# CONTROLSS_PWMXBAR_CONTROLSS_502D1000h register map
Vendor: Texas Instruments
Peripheral module from a debugger description file (folder AM261x).
Registers are 32-bit, read-write, reset 0x0 unless marked. A register's access mark holds for its fields unless they carry their own. Offsets are as the file gives them; lines under a group give offsets from that group; [hi:lo] are bit positions; {n}, {i} and the like mark numbered series; 'fields as' and 'values as' point back to an identical list; <NAME> marks a mode.

## CONTROLSS
0x10 CONTROLSS_PWMXBAR_STATUS ro — Output Signal Status.
  [29:0] PWMXBAR_STATUS_STS — Output Signal Status
0x14 CONTROLSS_PWMXBAR_FLAGINVERT — Output Signal Invert Before Latch.
  [29:0] PWMXBAR_FLAGINVERT_INVERT — Output Signal Invert Before Latch
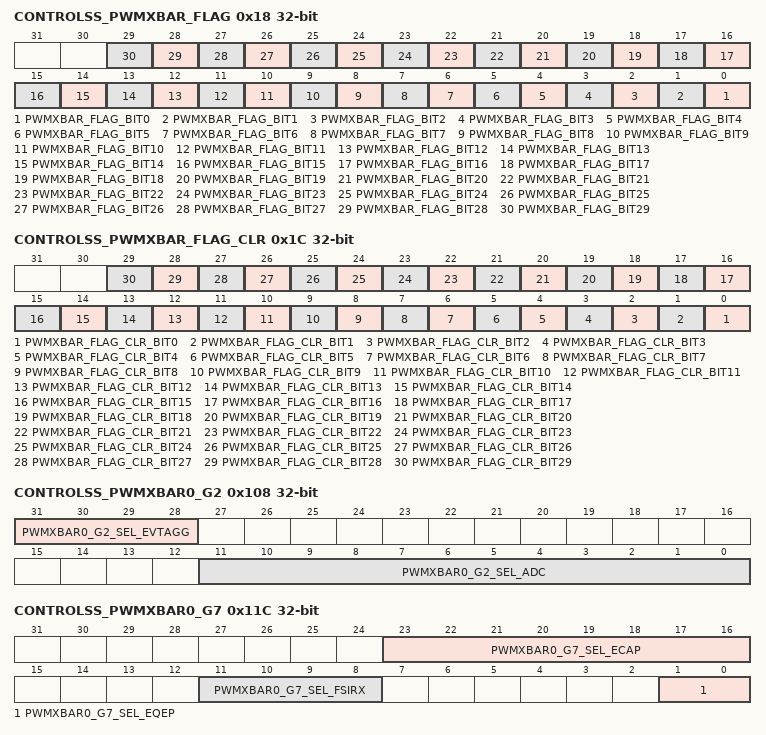
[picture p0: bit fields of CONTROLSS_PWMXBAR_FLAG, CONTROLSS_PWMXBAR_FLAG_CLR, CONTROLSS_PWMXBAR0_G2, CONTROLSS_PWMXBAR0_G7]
0x18 CONTROLSS_PWMXBAR_FLAG access not given — Output Signal Latched Flag.
  [n] PWMXBAR_FLAG_BIT{n} (n=0..29) — Output Signal Latched Flag (access R/W1TC)
0x1C CONTROLSS_PWMXBAR_FLAG_CLR — Output Signal Latched Flag Clear.
  [n] PWMXBAR_FLAG_CLR_BIT{n} (n=0..29) — Output Signal Latched Flag Clear
{0x100+0x40*i} CONTROLSS_PWMXBAR{i}_G0 (i=0..15) — PWM XBAR {i} Input Select.
  [17:0] PWMXBAR{i}_G0_SEL — PWM XBAR{i} G0 Input Select0:CMP12SS0.CTRIPL1:CMP12SS0.CTRIPH2:CMP12SS1.CTRIPL3:CMP12SS1.CTRIPH4:CMP12SS2.CTRIPL5:CMP12SS2.CTRIPH6:CMP12SS3.CTRIPL7:CMP12SS3.CTRIPH8:CMP12SS4.CTRIPL9:CMP12SS4.CTRIPH10:CMP12SS5.CTRIPL11:CMP12SS5.CTRIPH12:CMP12SS6.CTRIPL13:CMP12SS6.CTRIPH14:CMP12SS7.CTRIPL15:CMP12SS7.CTRIPH16:CMP12SS8.CTRIPL17:CMP12SS8.CTRIPH
{0x104+0x40*i} CONTROLSS_PWMXBAR{i}_G1 (i=0..29) — PWM XBAR {i} Input Select.
  [23:0] PWMXBAR{i}_G1_SEL — PWM XBAR{i} G1 Input Select0:SDFM0.FILT1CEVT11:SDFM0.FILT1CEVT22:SDFM0.FILT1COMPHZ3:SDFM0.FILT2CEVT14:SDFM0.FILT2CEVT25:SDFM0.FILT2COMPHZ6:SDFM0.FILT3CEVT17:SDFM0.FILT3CEVT28:SDFM0.FILT3COMPHZ9:SDFM0.FILT4CEVT110:SDFM0.FILT4CEVT211:SDFM0.FILT4COMPHZ12:SDFM1.FILT1CEVT113:SDFM1.FILT1CEVT214:SDFM1.FILT1COMPHZ15:SDFM1.FILT2CEVT116:SDFM1.FILT2CEVT217:SDFM1.FILT2COMPHZ18:SDFM1.FILT3CEVT119:SDFM1.FILT3CEVT220:SDFM1.FILT3COMPHZ21:SDFM1.FILT4CEVT122:SDFM1.FILT4CEVT223:SDFM1.FILT4COMPHZ
0x108 CONTROLSS_PWMXBAR0_G2 — PWM XBAR 0 Input Select.
  [31:28] PWMXBAR0_G2_SEL_EVTAGG — PWM XBAR0 G2 Input Select 2831:ADC_ASC_CHECKEVENT[3:0]
  [11:0] PWMXBAR0_G2_SEL_ADC — PWM XBAR0 G2 Input Select1:ADC0.EVT22:ADC0.EVT33:ADC0.EVT44:ADC1.EVT15:ADC1.EVT26:ADC1.EVT37:ADC1.EVT48:ADC2.EVT19:ADC2.EVT210:ADC2.EVT311:ADC2.EVT4
{0x10C+0x40*i} CONTROLSS_PWMXBAR{i}_G3 (i=0..29) — PWM XBAR {i} Input Select.
  [31:0] PWMXBAR{i}_G3_SEL — PWM XBAR{i} G3 input bit select. Input source is INPUT XBAR.1:INPUT XBAR output bit[x] selected0:INPUT XBAR output bit[x] is de-selected
{0x110+0x40*i} CONTROLSS_PWMXBAR{i}_G4 (i=0..29) — PWM XBAR {i} Input Select.
  [9:0] PWMXBAR{i}_G4_SEL — PWM XBAR{i} G4 input bit select. Input source is PWM TRIPOUT.1:PWM TRIPOUT bit[x] selected0:PWM TRIPOUT bit[x] is de-selected
{0x114+0x40*i} CONTROLSS_PWMXBAR{i}_G5 (i=0..29) — PWM XBAR {i} Input Select.
  [9:0] PWMXBAR{i}_G5_SEL — PWM XBAR{i} G5 input bit select. Input source is PWM DEL TRIP1:PWM DEL TRIP bit[x] selected0:PWM DEL TRIP bit[x] is de-selected
{0x118+0x40*i} CONTROLSS_PWMXBAR{i}_G6 (i=0..29) — PWM XBAR {i} Input Select.
  [9:0] PWMXBAR{i}_G6_SEL — PWM XBAR{i} G6 input bit select. Input source is PWM DEL ACTIVE1:PWM DEL ACTIVE bit[x] selected0:PWM DEL ACTIVE bit[x] is de-selected
0x11C CONTROLSS_PWMXBAR0_G7 — PWM XBAR 0 Input Select.
  [23:16] PWMXBAR0_G7_SEL_ECAP — PWM XBAR0 G7 Input Select2316:ECAP[7:0].TRIPOUT
  [11:8] PWMXBAR0_G7_SEL_FSIRX — PWM XBAR0 G7 Input Select8:FSIRX0.RX_TRIG09:FSIRX0.RX_TRIG110:FSIRX0.RX_TRIG211:FSIRX0.RX_TRIG3
  [1:0] PWMXBAR0_G7_SEL_EQEP — PWM XBAR0 G7 Input Select0:EQEP0.ERR1:EQEP1.ERR
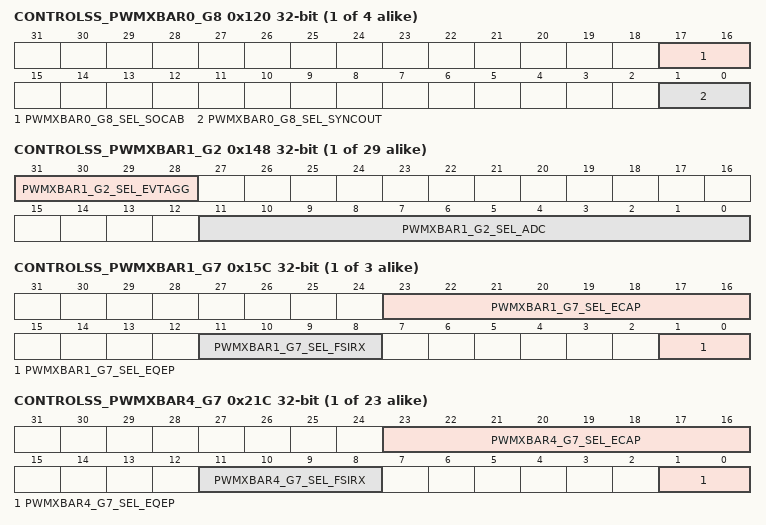
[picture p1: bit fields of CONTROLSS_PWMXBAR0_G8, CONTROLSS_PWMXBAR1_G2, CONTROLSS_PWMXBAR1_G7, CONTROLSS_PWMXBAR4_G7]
{0x120+0x40*i} CONTROLSS_PWMXBAR{i}_G8 (i=0..3) — PWM XBAR {i} Input Select.
  [17:16] PWMXBAR{i}_G8_SEL_SOCAB — PWM XBAR{i} G8 Input Select16:ADCSOCAB.OUTSOCA17:ADCSOCAB.OUTSOCB
  [1:0] PWMXBAR{i}_G8_SEL_SYNCOUT — PWM XBAR{i} G8 Input Select0:SYNCOUTXBAR0.TRIPOUT1:SYMCOUTXBAR1.TRIPOUT
{0x108+0x40*i} CONTROLSS_PWMXBAR{i}_G2 (i=1..29) — PWM XBAR {i} Input Select.
  [31:28] PWMXBAR{i}_G2_SEL_EVTAGG — PWM XBAR{i} G2 Input Select2831:ADC_ASC_CHECKEVENT[3:0]
  [11:0] PWMXBAR{i}_G2_SEL_ADC — PWM XBAR{i} G2 Input Select1:ADC0.EVT22:ADC0.EVT33:ADC0.EVT44:ADC1.EVT15:ADC1.EVT26:ADC1.EVT37:ADC1.EVT48:ADC2.EVT19:ADC2.EVT210:ADC2.EVT311:ADC2.EVT4
{0x11C+0x40*i} CONTROLSS_PWMXBAR{i}_G7 (i=1..3) — PWM XBAR {i} Input Select.
  [23:16] PWMXBAR{i}_G7_SEL_ECAP — PWM XBAR1 G7 Input Select2316:ECAP[7:0].TRIPOUT
  [11:8] PWMXBAR{i}_G7_SEL_FSIRX — PWM XBAR1 G7 Input Select8:FSIRX0.RX_TRIG09:FSIRX0.RX_TRIG110:FSIRX0.RX_TRIG211:FSIRX0.RX_TRIG3
  [1:0] PWMXBAR{i}_G7_SEL_EQEP — PWM XBAR1 G7 Input Select0:EQEP0.ERR1:EQEP1.ERR
{0x11C+0x40*i} CONTROLSS_PWMXBAR{i}_G7 (i=4..26) — PWM XBAR {i} Input Select.
  [23:16] PWMXBAR{i}_G7_SEL_ECAP — PWM XBAR{i} G7 Input Select2316:ECAP[7:0].TRIPOUT
  [11:8] PWMXBAR{i}_G7_SEL_FSIRX — PWM XBAR{i} G7 Input Select8:FSIRX0.RX_TRIG09:FSIRX0.RX_TRIG110:FSIRX0.RX_TRIG211:FSIRX0.RX_TRIG3
  [1:0] PWMXBAR{i}_G7_SEL_EQEP — PWM XBAR{i} G7 Input Select0:EQEP0.ERR1:EQEP1.ERR
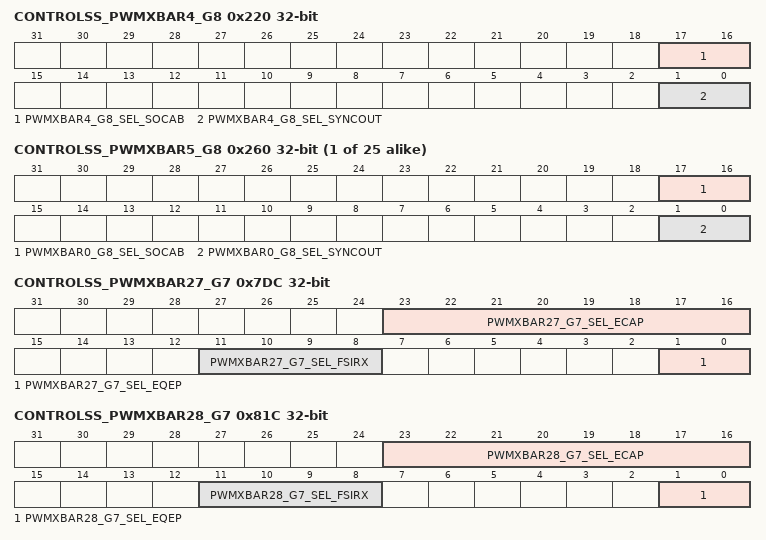
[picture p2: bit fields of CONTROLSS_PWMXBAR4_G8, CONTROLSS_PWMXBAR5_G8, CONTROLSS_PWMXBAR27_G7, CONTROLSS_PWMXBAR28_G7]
0x220 CONTROLSS_PWMXBAR4_G8 — PWM XBAR 4 Input Select.
  [17:16] PWMXBAR4_G8_SEL_SOCAB — PWM XBAR3 G8 Input Select16:ADCSOCAB.OUTSOCA17:ADCSOCAB.OUTSOCB
  [1:0] PWMXBAR4_G8_SEL_SYNCOUT — PWM XBAR3 G8 Input Select0:SYNCOUTXBAR0.TRIPOUT1:SYMCOUTXBAR1.TRIPOUT
{0x120+0x40*i} CONTROLSS_PWMXBAR{i}_G8 (i=5..29) — PWM XBAR {i} Input Select.
  fields as CONTROLSS_PWMXBAR0_G8
0x500 CONTROLSS_PWMXBAR16_G0 — PWM XBAR 16 Input Select.
  [17:0] PWMXBAR16_G0_SEL — PWM XBAR16 G0 Input Select0:CMP12SS0.CTRIPL1:CMP12SS0.CTRIPH2:CMP12SS1.CTRIPL3:CMP12SS1.CTRIPH4:CMP12SS2.CTRIPL5:CMP12SS2.CTRIPH6:CMP12SS3.CTRIPL7:CMP12SS3.CTRIPH8:CMP12SS4.CTRIPL9:CMP12SS4.CTRIPH10:CMP12SS5.CTRIPL11:CMP12SS5.CTRIPH12:CMP12SS6.CTRIPL13:CMP12SS6.CTRIPH14:CMP12SS7.CTRIPL15:CMP12SS7.CTRIPH16:CMP12SS8.CTRIPL17:CMP12SS8.CTRIPH18:CMP12SS9.CTRIPL19:CMP12SS9.CTRIPH
{0x100+0x40*i} CONTROLSS_PWMXBAR{i}_G0 (i=17..29) — PWM XBAR {i} Input Select.
  fields as CONTROLSS_PWMXBAR0_G0
0x7DC CONTROLSS_PWMXBAR27_G7 — PWM XBAR 27 Input Select.
  [23:16] PWMXBAR27_G7_SEL_ECAP — PWM XBAR27 G6 Input Select2316:ECAP[7:0].TRIPOUT
  [11:8] PWMXBAR27_G7_SEL_FSIRX — PWM XBAR27 G6 Input Select8:FSIRX0.RX_TRIG09:FSIRX0.RX_TRIG110:FSIRX0.RX_TRIG211:FSIRX0.RX_TRIG3
  [1:0] PWMXBAR27_G7_SEL_EQEP — PWM XBAR27 G6 Input Select0:EQEP0.ERR1:EQEP1.ERR
0x81C CONTROLSS_PWMXBAR28_G7 — PWM XBAR 28 Input Select.
  [23:16] PWMXBAR28_G7_SEL_ECAP — PWM XBAR28 G7 Input Select2316:ECAP[7:0].TRIPOUT
  [11:8] PWMXBAR28_G7_SEL_FSIRX — PWM XBAR28 G7 Input Select8:FSIRX0.RX_TRIG09:FSIRX0.RX_TRIG110:FSIRX0.RX_TRIG211:FSIRX0.RX_TRIG3
  [1:0] PWMXBAR28_G7_SEL_EQEP — PWM XBAR28 G7 Input Select0:EQEP0.ERR1:EQEP1.ERR
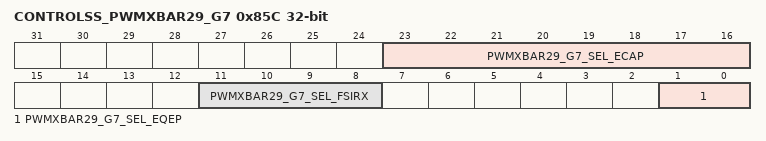
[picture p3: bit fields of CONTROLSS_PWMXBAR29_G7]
0x85C CONTROLSS_PWMXBAR29_G7 — PWM XBAR 29 Input Select.
  [23:16] PWMXBAR29_G7_SEL_ECAP — PWM XBAR29 G7 Input Select2316:ECAP[7:0].TRIPOUT
  [11:8] PWMXBAR29_G7_SEL_FSIRX — PWM XBAR29 G7 Input Select8:FSIRX0.RX_TRIG09:FSIRX0.RX_TRIG110:FSIRX0.RX_TRIG211:FSIRX0.RX_TRIG3
  [1:0] PWMXBAR29_G7_SEL_EQEP — PWM XBAR29 G7 Input Select0:EQEP0.ERR1:EQEP1.ERR
